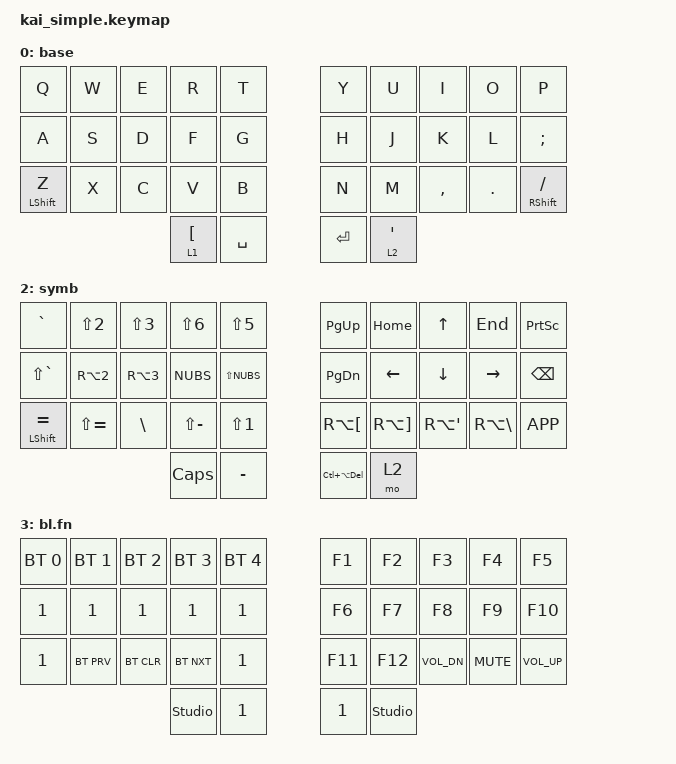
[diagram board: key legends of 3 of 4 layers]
// Copyright (c) 2022 The ZMK Contributors
// SPDX-License-Identifier: MIT

#include <dt-bindings/zmk/mouse.h>
#include <behaviors.dtsi>
#include <dt-bindings/zmk/bt.h>
#include <dt-bindings/zmk/keys.h>
#include <dt-bindings/zmk/pointing.h>

&mt {
    flavor = "tap-preferred";
    tapping_term_ms = <200>;
};




/ { 

    combos {
        compatible = "zmk,combos";
        combo_esc {
            timeout-ms = <50>;
            key-positions = <0 1>;
            bindings = <&kp ESC>;
        };
        
         combo_tab {
            timeout-ms = <50>;
            key-positions = <13 11>;
            bindings = <&kp TAB>;
        };
        
         combo_ralt {
            timeout-ms = <50>;
            key-positions = <18 17>;
            bindings = <&kp RALT>;
        };
        
          combo_lalt {
            timeout-ms = <50>;
            key-positions = <11 12>;
            bindings = <&kp LALT>;
        };
        
         combo_lgui {
            timeout-ms = <50>;
            key-positions = <4 3>;
            bindings = <&kp LGUI>;
        };
              
         combo_rgui {
            timeout-ms = <50>;
            key-positions = <5 6>;
            bindings = <&kp RGUI>;
        };
        
	 combo_rctrl {
            timeout-ms = <50>;
            key-positions = <18 19>;
            bindings = <&kp RCTRL>;
        };
	
	 combo_lctrl {
            timeout-ms = <50>;
            key-positions = <10 11>;
            bindings = <&kp LCTRL>;
        };
	
	combo_bspc {
            timeout-ms = <50>;
            key-positions = <8 9>;
            bindings = <&kp BSPC>;
        };
	
	combo_del {
            timeout-ms = <50>;
            key-positions = <7 8>;
            bindings = <&kp DEL>;
        };
	
	
	combo_layer3 {
            timeout-ms = <250>;
            key-positions = <0 9 20 29>;
            bindings = <&tog 3>;
        };

        
    };





     keymap {
                compatible = "zmk,keymap";

		
       		default_layer {
		display-name = "base";
		bindings = <
		&kp Q      &kp W &kp E &kp R &kp T 					&kp Y &kp U  &kp I    &kp O   &kp P 
		&kp A      &kp S &kp D &kp F &kp G 			        	&kp H &kp J  &kp K    &kp L   &kp SEMI
		&mt LSHIFT Z &kp X &kp C &kp V &kp B				        &kp N &kp M  &kp COMMA &kp DOT &mt RSHIFT SLASH
          				&lt 1 LBKT &kp SPACE  			&kp RET &lt 2 SQT
		>;
		};

       		left_layer {
		display-name = "numb";
		bindings = <
		&kp ESC         &studio_unlock	   &kp N4       &kp F5				&kp LS(N0) &kp N7  &kp N8 &kp N9  &kp N0 
		&kp KP_SLASH    &kp KP_ASTERISK    &kp KP_MINUS      &kp KP_PLUS     &kp RA(GRAVE) 			&kp TAB       &kp N4  &kp N5 &kp N6  &kp COMMA 
		&kp LSHIFT        &kp LCTRL 	   &kp RALT          &kp F11         &kp LA(F4) 			&kp KP_DOT    &kp N1  &kp N2 &kp N3  &kp BSPC 
					    						&trans  &kp SPACE   	&kp RET &none
		>;
		};
		
		right_layer {
		display-name = "symb";
		bindings = <
		&kp GRAVE       &kp LS(N2)  &kp LS(N3)  &kp LS(N6)   &kp LS(N5)		&kp PG_UP    &kp HOME     &kp UP      &kp END       &kp PSCRN 
		&kp LS(GRAVE)   &kp RA(N2)  &kp RA(N3)  &kp NUBS        &kp LS(NUBS)		&kp PG_DN    &kp LEFT     &kp DOWN    &kp RIGHT     &kp BSPC
		&mt LSHIFT EQUAL  &kp LS(EQUAL)  &kp BSLH       &kp LS(MINUS)   &kp LS(N1)    	        &kp RA(LBKT) &kp RA(RBKT) &kp RA(SQT) &kp RA(BSLH)  &kp K_APP
									  &kp CAPS &kp MINUS  	    &kp LC(LA(DEL))  &mo 2 
		>;
		};	
		
		tri_layer {
		display-name = "bl.fn";
		bindings = <
		&bt BT_SEL 0  &bt BT_SEL 1  &bt BT_SEL 2  &bt BT_SEL 3  &bt BT_SEL 4 			&kp F1   &kp F2   &kp F3        &kp F4      &kp F5
		&kp N1     &kp N1     &kp N1     &kp N1     &kp N1  			&kp F6   &kp F7   &kp F8        &kp F9      &kp F10 
		&kp N1     &bt BT_PRV    &bt BT_CLR    &bt BT_NXT    &kp N1   			&kp F11  &kp F12  &kp K_VOL_DN  &kp K_MUTE  &kp K_VOL_UP   
								&studio_unlock &kp N1  	     &kp N1 &studio_unlock 
		>;
		};	
        extra1 {
            status = "reserved";
        };

        extra2 {
            status = "reserved";
        };
	};
};
